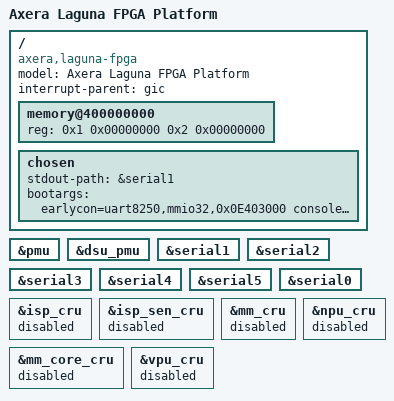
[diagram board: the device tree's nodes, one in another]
/* SPDX-License-Identifier: GPL-2.0+
 *
 * Axera Laguna FPGA Platform device tree
 *
 * Copyright (C) 2024 Charleye <wangkart@aliyun.com>
 */

/dts-v1/;
#define CONFIG_LUA_FPGA_VA
#define CONFIG_LUA_SAFETY_INIT

#include <dt-bindings/interrupt-controller/arm-gic.h>
#include <dt-bindings/mfd/laguna-syscon.h>
#include <dt-bindings/mfd/laguna-cru.h>
#include <dt-bindings/reset/laguna-reset.h>
#include <dt-bindings/clock/laguna-clock.h>

#ifdef CONFIG_LUA_SAFETY_INIT
#include "laguna-safety-clocks-fpga.dtsi"
#include "laguna-safety-cru.dtsi"
#include "laguna-safety.dtsi"
#endif

#include "laguna-global-ctrl.dtsi"
#include "laguna-clocks-fpga.dtsi"
#include "laguna-cru.dtsi"
#include "laguna.dtsi"
/ {
	compatible = "axera,laguna-fpga";
	model = "Axera Laguna FPGA Platform";
	#address-cells = <2>;
	#size-cells = <2>;
	interrupt-parent = <&gic>;

	memory@400000000 {
		reg = <0x1 0x00000000 0x2 0x00000000>;
		device_type = "memory";
	};

	chosen {
		stdout-path = &serial1;
		bootargs = "earlycon=uart8250,mmio32,0x0E403000 console=ttyS1,115200n8 rdinit=/init rw loglevel=10 clk_ignore_unused";
	};
};

&pmu {
	status = "okay";
};

&dsu_pmu {
	status = "okay";
};

&serial1 {
	status = "okay";
};

&serial2 {
	status = "okay";
};

&serial3 {
	status = "okay";
};

&serial4 {
	status = "okay";
};

&serial5 {
	status = "okay";
};

#ifdef CONFIG_LUA_SAFETY_INIT
&serial0 {
	status = "okay";
};
#endif

#if defined(CONFIG_LUA_FPGA_VA)
&isp_cru {
	status = "disabled";
};

&isp_sen_cru {
	status = "disabled";
};

&mm_cru {
	status = "disabled";
};

&mm_core_cru {
	status = "disabled";
};

&npu_cru {
	status = "disabled";
};

&vpu_cru {
	status = "disabled";
};
#endif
